# EFR32BG21A020F1024IM32 register map
Vendor: Silicon Labs; Series: EFR32; File version: B
Registers are 32-bit, read-write, reset 0x0 unless marked. A register's access mark holds for its fields unless they carry their own. Offsets are from the block's base; [hi:lo] are bit positions; {n}, {i} and the like mark numbered series; 'fields as' and 'values as' point back to an identical list.

## LDMAXBAR_S — LDMAXBAR_S Registers
Base 0x40044000
Same registers: LDMAXBAR_NS 0x50044000
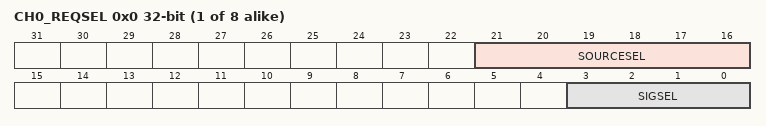
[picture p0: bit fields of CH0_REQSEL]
{0x0+4i} CH{i}_REQSEL (i=0..7)
  [21:16] SOURCESEL — Source Select
  [3:0] SIGSEL — Signal Select

## BURTC_S — BURTC_S Registers
Base 0x40064000
Same registers: BURTC_NS 0x50064000
0x00 IPVERSION ro
  [31:0] IPVERSION — IP Version ID
0x04 EN
  [0] EN — BURTC Enable
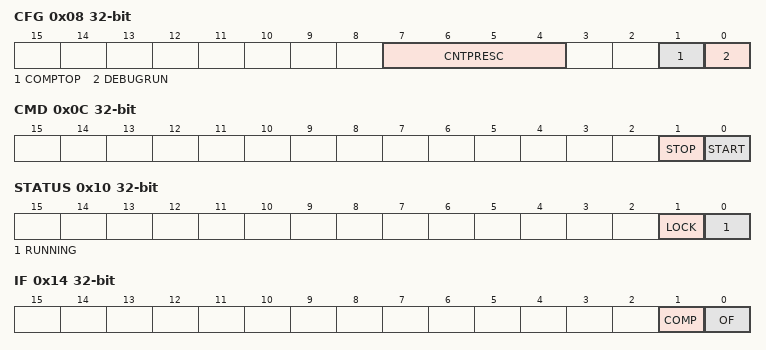
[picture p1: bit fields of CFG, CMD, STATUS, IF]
0x08 CFG
  [7:4] CNTPRESC — Counter prescaler value.
    0=DIV1 (CLK_CNT = (BURTC LF CLK)/1); 1=DIV2 (CLK_CNT = (BURTC LF CLK)/2); 2=DIV4 (CLK_CNT = (BURTC LF CLK)/4); 3=DIV8 (CLK_CNT = (BURTC LF CLK)/8); 4=DIV16 (CLK_CNT = (BURTC LF CLK)/16); 5=DIV32 (CLK_CNT = (BURTC LF CLK)/32); 6=DIV64 (CLK_CNT = (BURTC LF CLK)/64); 7=DIV128 (CLK_CNT = (BURTC LF CLK)/128); 8=DIV256 (CLK_CNT = (BURTC LF CLK)/256); 9=DIV512 (CLK_CNT = (BURTC LF CLK)/512); 10=DIV1024 (CLK_CNT = (BURTC LF CLK)/1024); 11=DIV2048 (CLK_CNT = (BURTC LF CLK)/2048); 12=DIV4096 (CLK_CNT = (BURTC LF CLK)/4096); 13=DIV8192 (CLK_CNT = (BURTC LF CLK)/8192); 14=DIV16384 (CLK_CNT = (BURTC LF CLK)/16384); 15=DIV32768 (CLK_CNT = (BURTC LF CLK)/32768)
  [1] COMPTOP — Compare Channel is Top Value
    0=DISABLE (The top value of the BURTC is 4294967295 (0xFFFFFFFF)); 1=ENABLE (The top value of the BURTC is given by COMP)
  [0] DEBUGRUN — Debug Mode Run Enable
    0=DISABLE (BURTC is frozen in debug mode); 1=ENABLE (BURTC is running in debug mode)
0x0C CMD wo
  [1] STOP — Stop BURTC counter
  [0] START — Start BURTC counter
0x10 STATUS ro
  [1] LOCK — Configuration Lock Status
    0=UNLOCKED (All BURTC lockable registers are unlocked.); 1=LOCKED (All BURTC lockable registers are locked.)
  [0] RUNNING — BURTC running status
0x14 IF
  [1] COMP — Compare Match Interrupt Flag
  [0] OF — Overflow Interrupt Flag
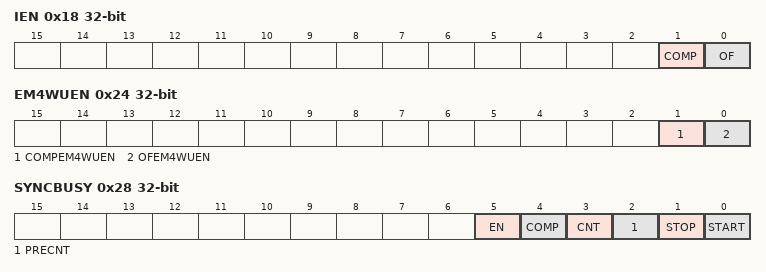
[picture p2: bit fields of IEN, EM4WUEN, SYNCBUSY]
0x18 IEN
  fields as IF
0x1C PRECNT
  [14:0] PRECNT — Pre-Counter Value
0x20 CNT
  [31:0] CNT — Counter Value
0x24 EM4WUEN
  [1] COMPEM4WUEN — Compare Match EM4 Wakeup Enable
  [0] OFEM4WUEN — Overflow EM4 Wakeup Enable
0x28 SYNCBUSY ro
  [5] EN — Sync busy for EN
  [4] COMP — Sync busy for COMP
  [3] CNT — Sync busy for CNT
  [2] PRECNT — Sync busy for PRECNT
  [1] STOP — Sync busy for STOP
  [0] START — Sync busy for START
0x2C LOCK wo reset 0xAEE8
  [15:0] LOCKKEY — Configuration Lock Key
    0xAEE8=UNLOCK (Write to unlock all BURTC lockable registers)
0x30 COMP
  [31:0] COMP — Compare Value

## SYSCFG_S — SYSCFG_S Registers
Base 0x4007C000
Same registers: SYSCFG_NS 0x5007C000
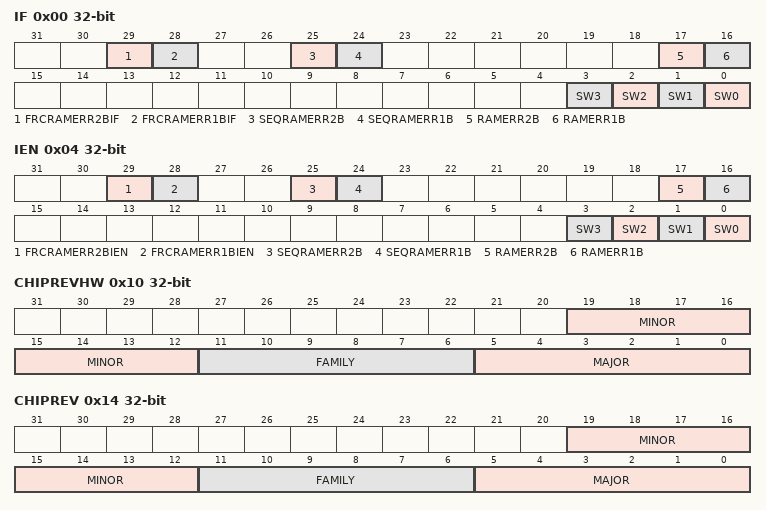
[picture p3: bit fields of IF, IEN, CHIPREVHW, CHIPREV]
0x00 IF
  [29] FRCRAMERR2BIF — FRCRAM 2-bit ECC Error Interrupt flag
  [28] FRCRAMERR1BIF — FRCRAM 1-bit ECC Error Interrupt flag
  [25] SEQRAMERR2B — SEQRAM 2-bit ECC Error Interrupt flag
  [24] SEQRAMERR1B — SEQRAM 1-bit ECC Error Interrupt flag
  [17] RAMERR2B — RAM 2-bit ECC Error Interrupt flag
  [16] RAMERR1B — RAM 1-bit ECC Error Interrupt flag
  [n] SW{n} (n=0..3) — Software Interrupt {n}
0x04 IEN
  [29] FRCRAMERR2BIEN — FRCRAM 2-bit ECC Error Interrupt enable
  [28] FRCRAMERR1BIEN — FRCRAM 1-bit ECC Error Interrupt enable
  [25] SEQRAMERR2B — SEQRAM 2-bit ECC Error Interrupt enable
  [24] SEQRAMERR1B — SEQRAM 1-bit ECC Error Interrupt enable
  [17] RAMERR2B — RAM 2-bit ECC Error Interrupt enable
  [16] RAMERR1B — RAM 1-bit ECC Error Interrupt enable
  [n] SW{n} (n=0..3) — Software interrupt {n}
0x10 CHIPREVHW
  [19:12] MINOR — Chip Rev Minor value
  [11:6] FAMILY — Chip Family value
  [5:0] MAJOR — Chip Rev Major value
0x14 CHIPREV
  [19:12] MINOR — Part Revision Minor value
  [11:6] FAMILY — Part Family value
  [5:0] MAJOR — Part Revision Major value
0x24 CFGSYSTIC
  [0] SYSTICEXTCLKEN — SysTick External Clock Enable
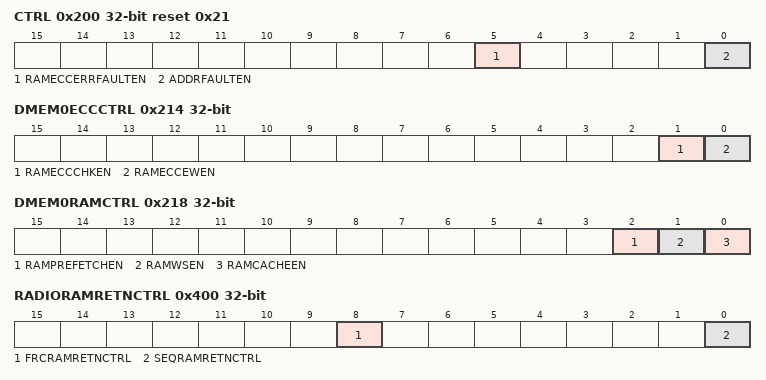
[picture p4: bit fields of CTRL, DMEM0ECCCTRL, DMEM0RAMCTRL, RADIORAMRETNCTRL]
0x200 CTRL reset 0x21
  [5] RAMECCERRFAULTEN — Two bit ECC Error Bus Fault Response Enable
  [0] ADDRFAULTEN — Invalid Address Bus Fault Response Enable
0x208 DMEM0RETNCTRL
  [4:0] RAMRETNCTRL — DMEM0 blockset retention control
    0=ALLON (None of the RAM blocks powered down); 16=BLK5 (Power down RAM block 5 (address range 0x20014000-0x20017FFF)); 24=BLK4TO5 (Power down RAM blocks 4 and above (address range 0x20010000-0x20017FFF)); 28=BLK3TO5 (Power down RAM blocks 3 and above (address range 0x2000C000-0x20017FFF)); 30=BLK2TO5 (Power down RAM blocks 2 and above (address range 0x20008000-0x20017FFF)); 31=BLK1TO5 (Power down RAM blocks 1 and above (address range 0x20004000-0x20017FFF))
0x210 DMEM0ECCADDR ro
  [31:0] DMEM0ECCADDR — DMEM0 RAM ECC Error Address
0x214 DMEM0ECCCTRL
  [1] RAMECCCHKEN — RAM ECC Check Enable
  [0] RAMECCEWEN — RAM ECC Write Enable
0x218 DMEM0RAMCTRL
  [2] RAMPREFETCHEN — RAM Prfetch Enable
  [1] RAMWSEN — RAM WAIT STATE Enable
  [0] RAMCACHEEN — RAM CACHE Enable
0x400 RADIORAMRETNCTRL
  [8] FRCRAMRETNCTRL — FRCRAM Memory Shutdown Control Register
    0=ALLON (FRCRAM not powered down); 1=FRCBLK (Power down FRCRAM (address range 0x50002000-0x50002FFF))
  [0] SEQRAMRETNCTRL — SEQRAM Memory Shutdown Control Register
    0=ALLON (SEQRAM not powered down); 1=SEQBLK (Power down SEQRAM (address range 0x50000000-0x50001FFF))
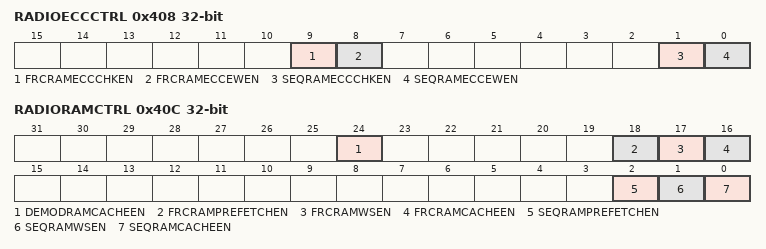
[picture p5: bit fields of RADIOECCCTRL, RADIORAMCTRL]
0x408 RADIOECCCTRL
  [9] FRCRAMECCCHKEN — FRCRAM ECC Check Enable
  [8] FRCRAMECCEWEN — FRCRAM ECC Write Enable
  [1] SEQRAMECCCHKEN — SEQRAM ECC Check Enable
  [0] SEQRAMECCEWEN — SEQRAM ECC Write Enable
0x40C RADIORAMCTRL
  [24] DEMODRAMCACHEEN — DEMODRAM CACHE Enable
  [18] FRCRAMPREFETCHEN — FRCRAM Prfetch Enable
  [17] FRCRAMWSEN — FRCRAM WAIT STATE Enable
  [16] FRCRAMCACHEEN — FRCRAM CACHE Enable
  [2] SEQRAMPREFETCHEN — SEQRAM Prfetch Enable
  [1] SEQRAMWSEN — SEQRAM WAIT STATE Enable
  [0] SEQRAMCACHEEN — SEQRAM CACHE Enable
0x410 SEQRAMECCADDR ro
  [31:0] SEQRAMECCADDR — SEQRAM ECC Error Address
0x414 FRCRAMECCADDR ro
  [31:0] FRCRAMECCADDR — FRCRAM ECC Error Address
